# RZT2ME register map
Vendor: Renesas Electronics Corporation; Series: RZT; File version: 1.00.00
CPU: other r0p0, little endian, MPU, no FPU, VTOR, 4 interrupt priority bits, 624 interrupts
Registers are 32-bit, read-write, reset 0x0 unless marked. A register's access mark holds for its fields unless they carry their own. Offsets are from the block's base; [hi:lo] are bit positions; {n}, {i} and the like mark numbered series; 'fields as' and 'values as' point back to an identical list.

## ICU — Interrupt Controller
Base 0x81048000
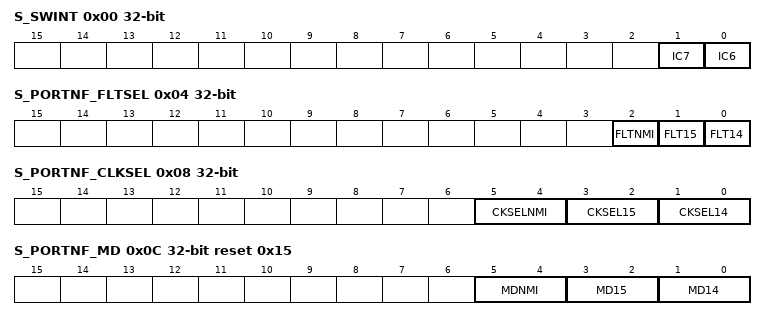
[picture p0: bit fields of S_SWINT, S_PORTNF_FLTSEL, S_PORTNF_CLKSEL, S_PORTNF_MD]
0x00 S_SWINT wo — Software Interrupt Register for Safety Register
  [1] IC7 — Software Interrupt register
  [0] IC6 — Software Interrupt register
0x04 S_PORTNF_FLTSEL — Interrupt Noise Filter Enable Register for Safety Register
  [all] fields
    0=Disable; 1=Enable
  [2] FLTNMI — Noise filter enable for NMI
  [1] FLT15 — Noise filter enable for IRQ15
  [0] FLT14 — Noise filter enable for IRQ14
0x08 S_PORTNF_CLKSEL — Interrupt Noise Filter Setting Register for Safety Register
  [all] fields
    0=Divided by 1; 1=Divided by 8; 2=Divided by 32; 3=Divided by 64
  [5:4] CKSELNMI — Select noise filter sampling frequency dividend rate for NMI.
  [3:2] CKSEL15 — Select noise filter sampling frequency dividend rate for IRQ15.
  [1:0] CKSEL14 — Select noise filter sampling frequency dividend rate for IRQ14.
0x0C S_PORTNF_MD reset 0x15 — Interrupt Edge Detection Setting Register for Safety Register
  [5:4] MDNMI — Select detection mode for NMI
    0=Invert; 1=Falling edge; 2=Rising edge; 3=Falling and rising edges
  [3:2] MD15 — Select detection mode for IRQ15
    0=Low level; 1=Falling edge; 2=Rising edge; 3=Falling and rising edges
  [1:0] MD14 — Select detection mode for IRQ14
    values as MD15
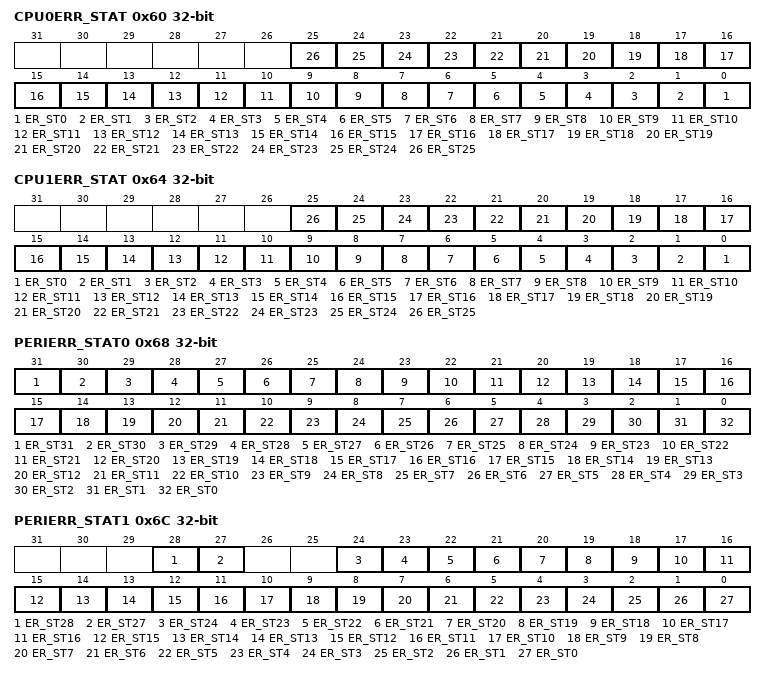
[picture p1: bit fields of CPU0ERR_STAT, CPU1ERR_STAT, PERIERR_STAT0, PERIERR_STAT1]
0x60 CPU0ERR_STAT ro — CPU0 Error Event Status Register
  [all] fields
    0=No error; 1=Error occurred
  [n] ER_ST{n} (n=0..25) — Indicate captured error status for CPU0_ERREVENT{n}
0x64 CPU1ERR_STAT ro — CPU1 Error Event Status Register
  [all] fields
    0=No error; 1=Error occurred
  [n] ER_ST{n} (n=0..25) — Indicate captured error status for CPU1_ERREVENT{n}
0x68 PERIERR_STAT0 ro — Peripheral Error Event Status Register 0
  [all] fields
    0=No error; 1=Error occurred
  [31] ER_ST31 — Indicate captured error status for DSMIF1_SCDE2
  [30] ER_ST30 — Indicate captured error status for DSMIF1_SCDE1
  [29] ER_ST29 — Indicate captured error status for DSMIF1_SCDE0
  [28] ER_ST28 — Indicate captured error status for DSMIF1_UTODE2
  [27] ER_ST27 — Indicate captured error status for DSMIF1_UTODE1
  [26] ER_ST26 — Indicate captured error status for DSMIF1_UTODE0
  [25] ER_ST25 — Indicate captured error status for DSMIF1_LTODE2
  [24] ER_ST24 — Indicate captured error status for DSMIF1_LTODE1
  [23] ER_ST23 — Indicate captured error status for DSMIF1_LTODE0
  [22] ER_ST22 — Indicate captured error status for DSMIF1_UTCSE
  [21] ER_ST21 — Indicate captured error status for DSMIF1_LTCSE
  [20] ER_ST20 — Indicate captured error status for DSMIF0_SCDE2
  [19] ER_ST19 — Indicate captured error status for DSMIF0_SCDE1
  [18] ER_ST18 — Indicate captured error status for DSMIF0_SCDE0
  [17] ER_ST17 — Indicate captured error status for DSMIF0_UTODE2
  [16] ER_ST16 — Indicate captured error status for DSMIF0_UTODE1
  [15] ER_ST15 — Indicate captured error status for DSMIF0_UTODE0
  [14] ER_ST14 — Indicate captured error status for DSMIF0_LTODE2
  [13] ER_ST13 — Indicate captured error status for DSMIF0_LTODE1
  [12] ER_ST12 — Indicate captured error status for DSMIF0_LTODE0
  [11] ER_ST11 — Indicate captured error status for DSMIF0_UTCSE
  [10] ER_ST10 — Indicate captured error status for DSMIF0_LTCSE
  [9] ER_ST9 — Indicate captured error status for USB_FDMAERR
  [8] ER_ST8 — Indicate captured error status for WDT_NMIUNDF1
  [7] ER_ST7 — Indicate captured error status for WDT_NMIUNDF0
  [6] ER_ST6 — Indicate captured error status for DMAC1_ERR
  [5] ER_ST5 — Indicate captured error status for DMAC0_ERR
  [4] ER_ST4 — Indicate captured error status for BSC_WTO
  [3] ER_ST3 — Indicate captured error status for CLMA2_INT
  [2] ER_ST2 — Indicate captured error status for CLMA1_INT
  [1] ER_ST1 — Indicate captured error status for CLMA0_INT
  [0] ER_ST0 — Indicate captured error status for CLMA3_INT
0x6C PERIERR_STAT1 ro — Peripheral Error Event Status Register 1
  [all] fields
    0=No error; 1=Error occurred
  [28] ER_ST28 — Indicate captured error status for MPU_DBGW
  [27] ER_ST27 — Indicate captured error status for MPU_DBGR
  [24] ER_ST24 — Indicate captured error status for MPU_USBF
  [23] ER_ST23 — Indicate captured error status for MPU_USBH
  [22] ER_ST22 — Indicate captured error status for MPU_GMACW
  [21] ER_ST21 — Indicate captured error status for MPU_GMACR
  [20] ER_ST20 — Indicate captured error status for MPU_DMACW1
  [19] ER_ST19 — Indicate captured error status for MPU_DMACR1
  [18] ER_ST18 — Indicate captured error status for MPU_DMACW0
  [17] ER_ST17 — Indicate captured error status for MPU_DMACR0
  [16] ER_ST16 — Indicate captured error status for CPU1WMPU
  [15] ER_ST15 — Indicate captured error status for CPU1RMPU
  [14] ER_ST14 — Indicate captured error status for LLPP_BUS_ERRINT
  [13] ER_ST13 — Indicate captured error status for MAIN_BUS_ERRINT
  [12] ER_ST12 — Indicate captured error status for SRAM3_OVF
  [11] ER_ST11 — Indicate captured error status for SRAM3_IE2
  [10] ER_ST10 — Indicate captured error status for SRAM3_IE1
  [9] ER_ST9 — Indicate captured error status for SRAM2_OVF
  [8] ER_ST8 — Indicate captured error status for SRAM2_IE2
  [7] ER_ST7 — Indicate captured error status for SRAM2_IE1
  [6] ER_ST6 — Indicate captured error status for SRAM1_OVF
  [5] ER_ST5 — Indicate captured error status for SRAM1_IE2
  [4] ER_ST4 — Indicate captured error status for SRAM1_IE1
  [3] ER_ST3 — Indicate captured error status for SRAM0_OVF
  [2] ER_ST2 — Indicate captured error status for SRAM0_IE2
  [1] ER_ST1 — Indicate captured error status for SRAM0_IE1
  [0] ER_ST0 — Indicate captured error status for DOC_DOPCI
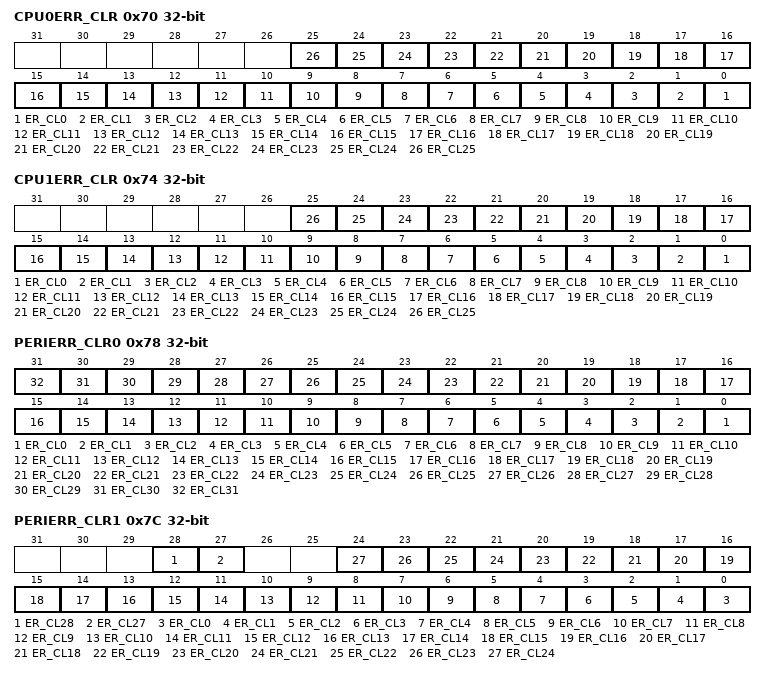
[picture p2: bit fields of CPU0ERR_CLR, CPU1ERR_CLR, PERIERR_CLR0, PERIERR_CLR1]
0x70 CPU0ERR_CLR wo — CPU0 Error Event Status Clear Register
  [n] ER_CL{n} (n=0..25) — Clear captured error status for CPU0ERR_STAT register by writing 1
0x74 CPU1ERR_CLR wo — CPU1 Error Event Status Clear Register
  [n] ER_CL{n} (n=0..25) — Clear captured error status for CPU1ERR_STAT register by writing 1
0x78 PERIERR_CLR0 wo — Peripheral Error Event Status Clear Register 0
  [n] ER_CL{n} (n=0..31) — Clear captured error status for PERIERR_STAT0 register by writing 1
0x7C PERIERR_CLR1 wo — Peripheral Error Event Status Clear Register 1
  [28] ER_CL28 — Clear captured error status for PERIERR_STAT1 register by writing 1
  [27] ER_CL27 — Clear captured error status for PERIERR_STAT1 register by writing 1
  [n] ER_CL{n} (n=0..24) — Clear captured error status for PERIERR_STAT1 register by writing 1
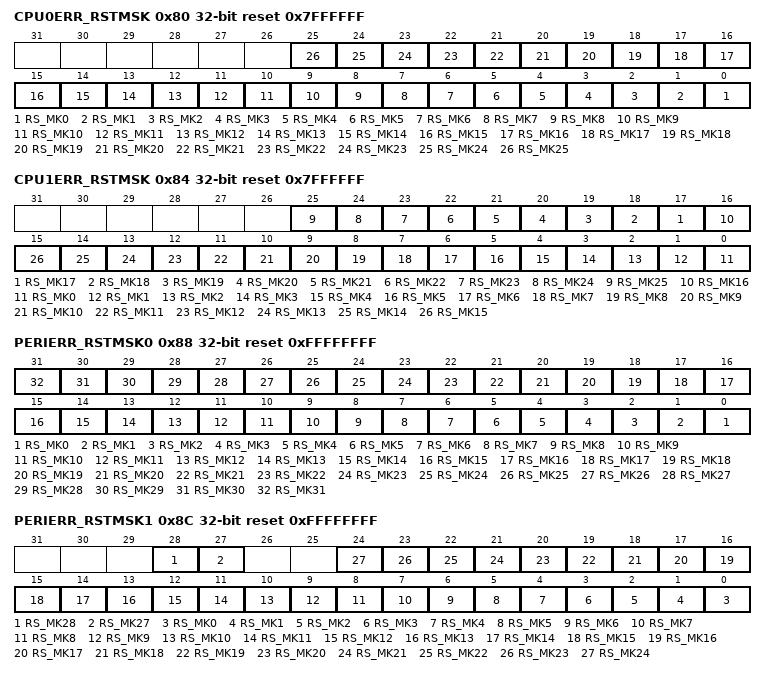
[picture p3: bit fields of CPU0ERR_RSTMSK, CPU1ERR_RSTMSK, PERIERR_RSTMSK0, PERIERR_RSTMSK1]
0x80 CPU0ERR_RSTMSK reset 0x7FFFFFF — CPU0 Error Event Reset Mask Register
  [all] fields
    0=Release; 1=Mask
  [n] RS_MK{n} (n=0..25) — Mask captured error status as a reset event for CPU0ERR_STAT
0x84 CPU1ERR_RSTMSK reset 0x7FFFFFF — CPU1 Error Event Reset Mask Register
  [all] fields
    0=Release; 1=Mask
  [n] RS_MK{n} (n=17..25) — Mask captured error status as a reset event for CPU1ERR_STAT
  [16] RS_MK16 — Mask captured error status as a reset event for CPU0ERR_STAT
  [n] RS_MK{n} (n=0..15) — Mask captured error status as a reset event for CPU1ERR_STAT
0x88 PERIERR_RSTMSK0 reset 0xFFFFFFFF — Peripheral Error Event Reset Mask Register 0
  [all] fields
    0=Release; 1=Mask
  [n] RS_MK{n} (n=0..31) — Mask captured error status as a reset event for PERIERR_STAT0
0x8C PERIERR_RSTMSK1 reset 0xFFFFFFFF — Peripheral Error Event Reset Mask Register 1
  [all] fields
    0=Release; 1=Mask
  [28] RS_MK28 — Mask captured error status as a reset event for PERIERR_STAT1
  [27] RS_MK27 — Mask captured error status as a reset event for PERIERR_STAT1
  [n] RS_MK{n} (n=0..24) — Mask captured error status as a reset event for PERIERR_STAT1
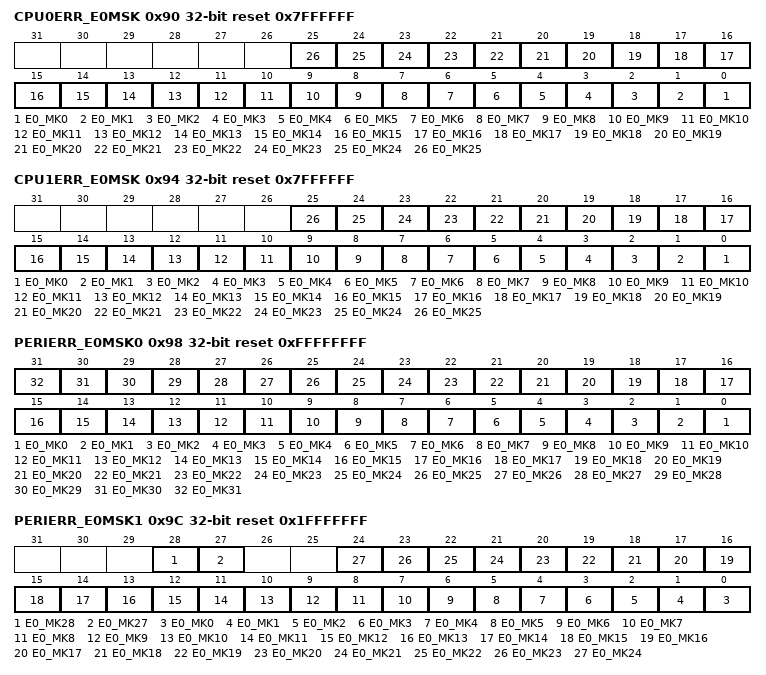
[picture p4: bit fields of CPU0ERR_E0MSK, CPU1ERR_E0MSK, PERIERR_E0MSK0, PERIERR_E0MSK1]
0x90 CPU0ERR_E0MSK reset 0x7FFFFFF — CPU0 E0 Error Event Mask Register
  [all] fields
    0=Release; 1=Mask
  [n] E0_MK{n} (n=0..25) — Mask captured error status as an CPU0_ERR0 event for CPU0ERR_STAT
0x94 CPU1ERR_E0MSK reset 0x7FFFFFF — CPU1 E0 Error Event Mask Register
  [all] fields
    0=Release; 1=Mask
  [n] E0_MK{n} (n=0..25) — Mask captured error status as an CPU1_ERR0 event for CPU1ERR_STAT
0x98 PERIERR_E0MSK0 reset 0xFFFFFFFF — Peripheral E0 Error Event Mask Register 0
  [all] fields
    0=Release; 1=Mask
  [n] E0_MK{n} (n=0..31) — Mask captured error status as an PERI_ERR0 event for PERIERR_STAT0
0x9C PERIERR_E0MSK1 reset 0x1FFFFFFF — Peripheral E0 Error Event Mask Register 1
  [all] fields
    0=Release; 1=Mask
  [28] E0_MK28 — Mask captured error status as an PERI_ERR0 event for PERIERR_STAT1
  [27] E0_MK27 — Mask captured error status as an PERI_ERR0 event for PERIERR_STAT1
  [n] E0_MK{n} (n=0..24) — Mask captured error status as an PERI_ERR0 event for PERIERR_STAT1
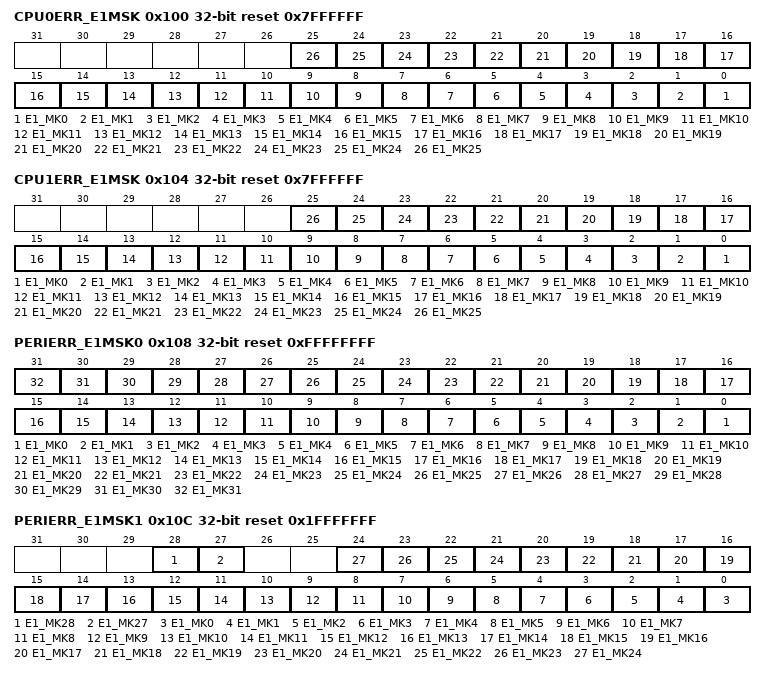
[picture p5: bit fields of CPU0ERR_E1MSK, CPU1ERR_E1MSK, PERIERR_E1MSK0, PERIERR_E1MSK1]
0x100 CPU0ERR_E1MSK reset 0x7FFFFFF — CPU0 E1 Error Event Mask Register
  [all] fields
    0=Release; 1=Mask
  [n] E1_MK{n} (n=0..25) — Mask captured error status as an CPU0_ERR1 event for CPU0ERR_STAT
0x104 CPU1ERR_E1MSK reset 0x7FFFFFF — CPU1 E1 Error Event Mask Register
  [all] fields
    0=Release; 1=Mask
  [n] E1_MK{n} (n=0..25) — Mask captured error status as an CPU1_ERR1 event for CPU1ERR_STAT
0x108 PERIERR_E1MSK0 reset 0xFFFFFFFF — Peripheral E1 Error Event Mask Register 0
  [all] fields
    0=Release; 1=Mask
  [n] E1_MK{n} (n=0..31) — Mask captured error status as an PERI_ERR1 event for PERIERR_STAT0
0x10C PERIERR_E1MSK1 reset 0x1FFFFFFF — Peripheral E1 Error Event Mask Register 1
  [all] fields
    0=Release; 1=Mask
  [28] E1_MK28 — Mask captured error status as an PERI_ERR1 event for PERIERR_STAT1
  [27] E1_MK27 — Mask captured error status as an PERI_ERR1 event for PERIERR_STAT1
  [n] E1_MK{n} (n=0..24) — Mask captured error status as an PERI_ERR1 event for PERIERR_STAT1
